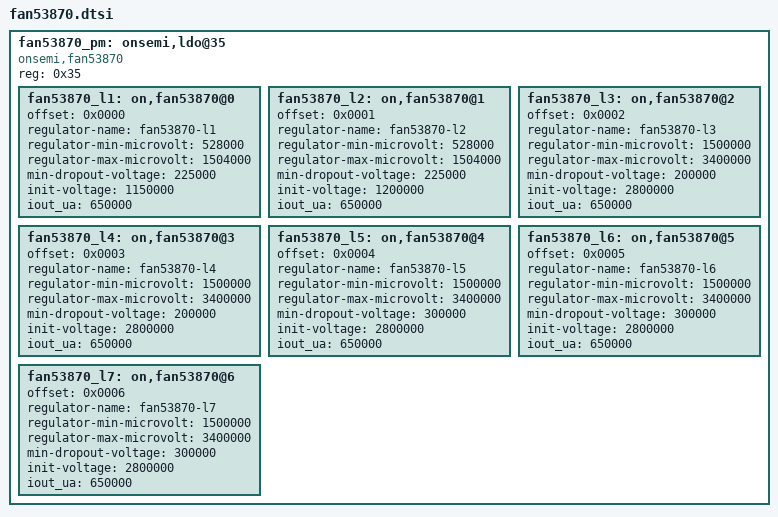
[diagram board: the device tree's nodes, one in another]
fan53870_pm:onsemi,ldo@35 {
	compatible = "onsemi,fan53870";
	reg = <0x35>;/*slave address*/

	fan53870_l1:on,fan53870@0{
		offset = /bits/ 16 <0x0000>;
		regulator-name ="fan53870-l1";
		regulator-min-microvolt = <528000>;
		regulator-max-microvolt = <1504000>;
		min-dropout-voltage = <225000>;
		init-voltage = <1150000>;
		iout_ua = <650000>;
	};

	fan53870_l2:on,fan53870@1{
		offset = /bits/ 16 <0x0001>;
		regulator-name ="fan53870-l2";
		regulator-min-microvolt = <528000>;
		regulator-max-microvolt = <1504000>;
		min-dropout-voltage = <225000>;
		init-voltage = <1200000>;
		iout_ua = <650000>;
	};

	fan53870_l3:on,fan53870@2{
		offset = /bits/ 16 <0x0002>;
		regulator-name ="fan53870-l3";
		regulator-min-microvolt = <1500000>;
		regulator-max-microvolt = <3400000>;
		min-dropout-voltage = <200000>;
		init-voltage = <2800000>;
		iout_ua = <650000>;
	};

	fan53870_l4:on,fan53870@3{
		offset = /bits/ 16 <0x0003>;
		regulator-name ="fan53870-l4";
		regulator-min-microvolt = <1500000>;
		regulator-max-microvolt = <3400000>;
		min-dropout-voltage = <200000>;
		init-voltage = <2800000>;
		iout_ua = <650000>;
	};

	fan53870_l5:on,fan53870@4{
		offset = /bits/ 16 <0x0004>;
		regulator-name ="fan53870-l5";
		regulator-min-microvolt = <1500000>;
		regulator-max-microvolt = <3400000>;
		min-dropout-voltage = <300000>;
		init-voltage = <2800000>;
		iout_ua = <650000>;
	};

	fan53870_l6:on,fan53870@5{
		offset = /bits/ 16 <0x0005>;
		regulator-name ="fan53870-l6";
		regulator-min-microvolt = <1500000>;
		regulator-max-microvolt = <3400000>;
		min-dropout-voltage = <300000>;
		init-voltage = <2800000>;
		iout_ua = <650000>;
	};

	fan53870_l7:on,fan53870@6{
		offset = /bits/ 16 <0x0006>;
		regulator-name ="fan53870-l7";
		regulator-min-microvolt = <1500000>;
		regulator-max-microvolt = <3400000>;
		min-dropout-voltage = <300000>;
		init-voltage = <2800000>;
		iout_ua = <650000>;
	};
};
